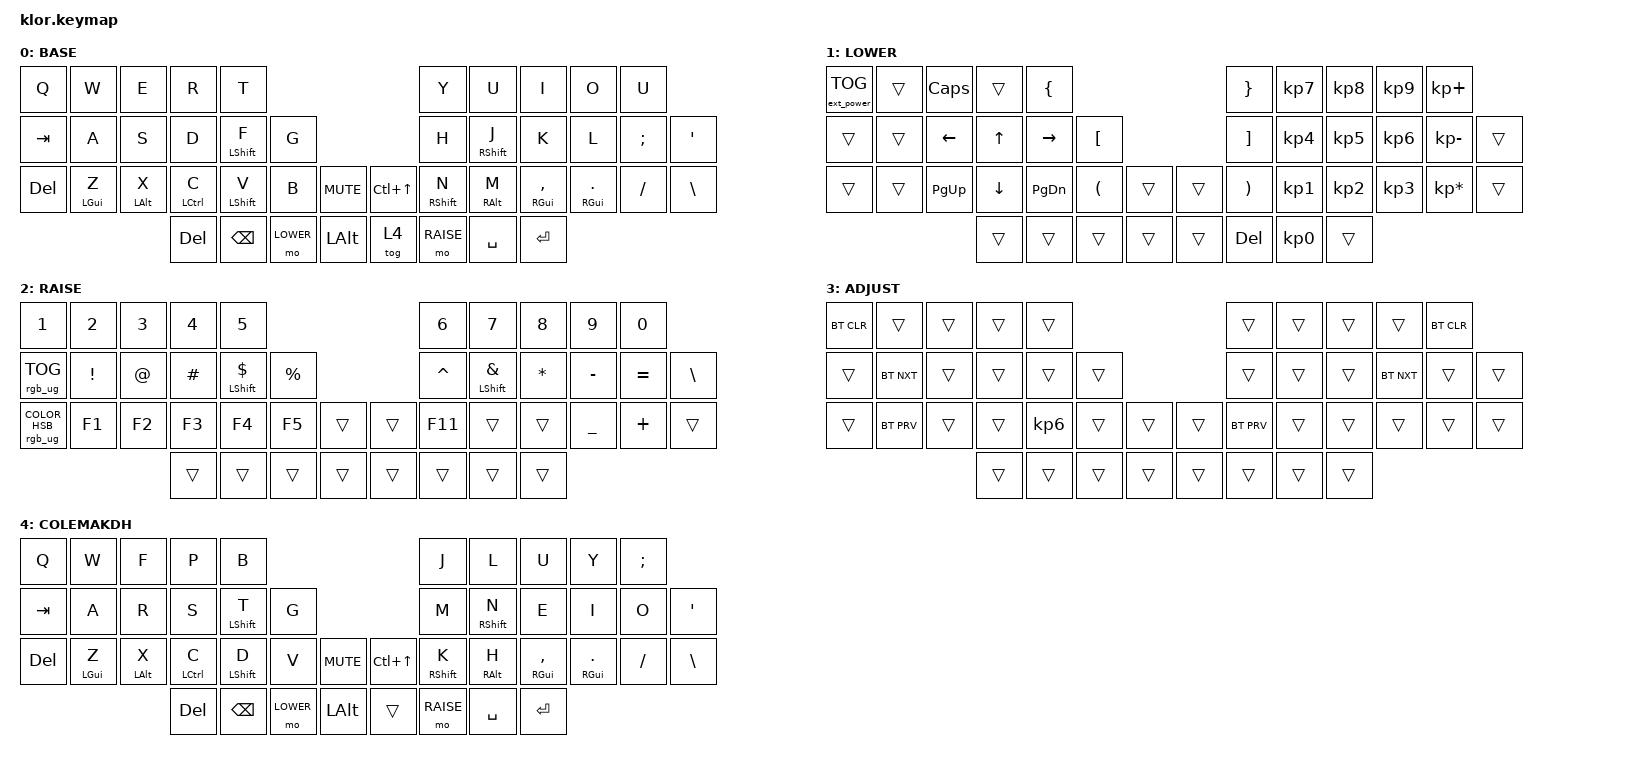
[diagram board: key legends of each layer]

//                               █         █    █            ▄▄▄▀▀▀▀▀▀▄▄▄        █▀▀▀▀▀▀▀▀▀▀█
//                               █        █     █          ▄▀            ▀▄      █          █
//                               █       █      █        ▄▀                ▀▄    █          █
//                               █      █       █        █                  █    █          █
//                               █     █        █       █                    █   █          █
//                               █    █         █       █                    █   █▄▄▄▄▄▄▄▄▄▄█
//                               █   █ █        █       █                    █   █      █
//                               █  █   █       █        █                  █    █       █
//                               █ █     █      █        ▀▄                ▄▀    █        █
//                               ██       █     █          ▀▄            ▄▀      █         █
//                               █         █    █▄▄▄▄▄▄▄▄    ▀▀▀▄▄▄▄▄▄▀▀▀        █          █
//
// ▄▄▄▄▄▄▄▄▄▄▄▄▄▄▄▄▄▄▄▄▄▄▄▄▄▄▄▄▄▄▄▄▄▄▄▄▄▄▄▄▄▄▄▄▄▄▄▄▄▄▄▄▄▄▄▄▄▄▄▄▄▄▄▄▄▄▄▄▄▄▄▄▄▄▄▄▄▄▄▄▄▄▄▄▄▄▄▄▄▄▄▄▄▄▄▄▄▄▄▄▄▄▄▄▄▄▄▄▄▄▄▄▄▄▄▄▄▄▄▄▄▄▄▄▄
       
#include <behaviors.dtsi>
#include <dt-bindings/zmk/keys.h>
#include <dt-bindings/zmk/backlight.h>
#include <dt-bindings/zmk/rgb.h>
#include <dt-bindings/zmk/bt.h>
#include <dt-bindings/zmk/outputs.h>
#include <dt-bindings/zmk/ext_power.h>


#define BASE   0
#define LOWER  1
#define RAISE  2
#define ADJUST 3
#define COLEMAKDH 4

/ {
    behaviors {
        hm: homerow_mods {
            compatible = "zmk,behavior-hold-tap";
            label = "HOMEROW_MODS";
            #binding-cells = <2>;
            tapping-term-ms = <150>;
            quick_tap_ms = <0>;
            flavor = "tap-preferred";
            bindings = <&kp>, <&kp>;
        };

&led_strip {
    chain-length = <21>;
};
        rgb_ug: rgb_ug {
            compatible = "zmk,behavior-rgb-underglow";
            label = "RGB_UG";
            #binding-cells = <2>;
        };

       bkl: bcklight {
            compatible = "zmk,behavior-backlight";
            label = "BCKLIGHT";
            #binding-cells = <2>;
       };
    };

    combos {
        compatible = "zmk,combos";
        combo_esc {
            timeout-ms = <50>;
            key-positions = <0 1>;
            bindings = <&kp ESC>;
        };
       left_bkt {
            bindings = <&kp LEFT_BRACKET>;
            key-positions = <1 2>;
            timeout-ms = <50>;
        };

        right_bkt {
            bindings = <&kp RIGHT_BRACKET>;
            key-positions = <2 3>;
            timeout-ms = <50>;
        };

        left_par {
            bindings = <&kp LEFT_PARENTHESIS>;
            key-positions = <12 13>;
            timeout-ms = <50>;
        };

        right_par {
            bindings = <&kp RIGHT_PARENTHESIS>;
            key-positions = <13 14>;
            timeout-ms = <50>;
        };

        left_brace {
            bindings = <&kp LEFT_BRACE>;
            key-positions = <25 26>;
            timeout-ms = <50>;
        };

        right_brace {
            bindings = <&kp RIGHT_BRACE>;
            key-positions = <26 27>;
            timeout-ms = <50>;
        };

        bac {
            bindings = <&kp BACKSLASH>;
            key-positions = <5 6>;
            timeout-ms = <50>;
        };

        pipe {
            bindings = <&kp PIPE>;
            key-positions = <3 4>;
            timeout-ms = <50>;
        };

        copy {
            bindings = <&kp LG(C)>;
            key-positions = <14 15>;
            timeout-ms = <50>;
        };

       paste {
            bindings = <&kp LG(V)>;
            key-positions = <16 17>;
            timeout-ms = <50>;
        };

        capslock {
            bindings = <&kp CAPS>;
            key-positions = <10 11>;
            timeout-ms = <50>;
        };

       studio {
            bindings = <&studio_unlock>;
            key-positions = <0 11>;
            timeout-ms = <50>;
        };
    };


        keymap {
                compatible = "zmk,keymap";
// ▄▄▄▄▄▄▄▄▄▄▄▄▄▄▄▄▄▄▄▄▄▄▄▄▄▄▄▄▄▄▄▄▄▄▄▄▄▄▄▄▄▄▄▄▄▄▄▄▄▄▄▄▄▄▄▄▄▄▄▄▄▄▄▄▄▄▄▄▄▄▄▄▄▄▄▄▄▄▄▄▄▄▄▄▄▄▄▄▄▄▄▄▄▄▄▄▄▄▄▄▄▄▄▄▄▄▄▄▄▄▄▄▄▄▄▄▄▄▄▄▄▄▄▄▄▄▄▄▄▄▄▄▄▄▄▄▄▄▄▄▄▄

                 base_layer {
// ┌───────────────────────────────────────────────────────────┐
label= "BASE"                                                ;
// └───────────────────────────────────────────────────────────┘
/*           ┌─────────┬─────────┬─────────┬─────────┬─────────┐                    ┌─────────┬─────────┬─────────┬─────────┬─────────┐
             │    Q    │    W    │    E    │    R    │    T    │                    │    Y    │    U    │    I    │    O    │    P    │   
   ┌─────────┼─────────┼─────────┼─────────┼─────────┼─────────┤                    ├─────────┼─────────┼─────────┼─────────┼─────────┼─────────┐
   │   TAB   │    A    │    S    │    D    │    F    │    G    │                    │    H    │    J    │    K    │    L    │    ;    │    "    │
   ├─────────┼─────────┼─────────┼─────────┼─────────┼─────────┤╭────────╮╭────────╮├─────────┼─────────┼─────────┼─────────┼─────────┼─────────┤
   │   DEL   │    Z    │    X    │    C    │    V    │    B    ││  MUTE  ││PLY/PSE ││    N    │    H    │    ,    │    .    │    /    │    \    │
   └─────────┴─────────┴─────────┼─────────┼─────────┼─────────┼╰────────╯╰────────╯┼─────────┼─────────┼─────────┼─────────┴─────────┴─────────┘
                                 │  DEL    │  BSPCE  │  LOWER  │   LOWER ││ TOG 4   │  SPACE  │  RAISE  │  ENTER  │  
                                 └─────────┴─────────┴─────────┴─────────┘└─────────┴─────────┴─────────┴─────────┘ */ 
 bindings = <
 //╷         ╷         ╷         ╷         ╷         ╷         ╷         ╷╷         ╷         ╷         ╷         ╷         ╷         ╷         ╷
              &kp Q     &kp W     &kp E     &kp R     &kp T                          &kp Y     &kp U     &kp I     &kp O     &kp U
    &kp TAB   &kp A     &kp S     &kp D   &hm LSHFT F &kp G                          &kp H   &hm RSHFT J &kp K     &kp L     &kp SEMI     &kp SQT
    &kp DEL   &hm LGUI Z     &hm LALT X     &hm LCTRL C     &hm LSHFT V     &kp B     &kp K_MUTE     &kp LC(UP)    &hm RSHFT N     &hm RALT M     &hm RGUI COMMA &hm RGUI DOT   &kp FSLH  &kp BSLH
                                  &kp DEL &kp BSPC &mo LOWER &kp LALT &tog 4 &mo RAISE &kp SPACE &kp RET     
                        >;
            sensor-bindings = <&inc_dec_kp C_VOL_UP C_VOL_DN &inc_dec_kp LC(LEFT) LC(RIGHT)>;
                };          

// ▄▄▄▄▄▄▄▄▄▄▄▄▄▄▄▄▄▄▄▄▄▄▄▄▄▄▄▄▄▄▄▄▄▄▄▄▄▄▄▄▄▄▄▄▄▄▄▄▄▄▄▄▄▄▄▄▄▄▄▄▄▄▄▄▄▄▄▄▄▄▄▄▄▄▄▄▄▄▄▄▄▄▄▄▄▄▄▄▄▄▄▄▄▄▄▄▄▄▄▄▄▄▄▄▄▄▄▄▄▄▄▄▄▄▄▄▄▄▄▄▄▄▄▄▄▄▄▄▄▄▄▄▄▄▄▄▄▄▄▄▄▄


                lower_layer {
// ┌───────────────────────────────────────────────────────────┐
label= "LOWER"                                                 ;
// └───────────────────────────────────────────────────────────┘
/*           ┌─────────┬─────────┬─────────┬─────────┬─────────┐                    ┌─────────┬─────────┬─────────┬─────────┬─────────┐
             │         │         │  CAPS   │         │    {    │                    │    }    │    7    │    8    │    9    │    +    │
   ┌─────────┼─────────┼─────────┼─────────┼─────────┼─────────┤                    ├─────────┼─────────┼─────────┼─────────┼─────────┼─────────┐
   │         │         │   LEFT  │    UP   │  RIGHT  │    [    │                    │    ]    │    4    │    5    │    6    │    -    │         │
   ├─────────┼─────────┼─────────┼─────────┼─────────┼─────────┤╭────────╮╭────────╮├─────────┼─────────┼─────────┼─────────┼─────────┼─────────┤
   │         │         │   P UP  │   DOWN  │ P DOWN  │    (    ││        ││        ││    )    │    1    │    2    │    3    │    *    │         │
   └─────────┴─────────┴─────────┼─────────┼─────────┼─────────┼╰────────╯╰────────╯┼─────────┼─────────┼─────────┼─────────┴─────────┴─────────┘
                                 │         │         │         │         ││         │         │    0    │         │  
                                 └─────────┴─────────┴─────────┴─────────┘└─────────┴─────────┴─────────┴─────────┘ */ 
 bindings = <
 //╷         ╷         ╷         ╷         ╷         ╷         ╷         ╷╷         ╷         ╷         ╷         ╷         ╷         ╷         ╷
    &ext_power EP_TOG   &trans    &kp CAPS    &trans    &kp LBRC                       &kp RBRC  &kp KP_N7 &kp KP_N8 &kp KP_N9 &kp KP_PLUS
    &trans    &trans    &kp LEFT  &kp UP  &kp RIGHT &kp LBKT                       &kp RBKT  &kp KP_N4 &kp KP_N5 &kp KP_N6 &kp KP_MINUS &trans
    &trans    &trans    &kp PG_UP &kp DOWN  &kp PG_DN &kp LPAR  &trans     &trans    &kp RPAR  &kp KP_N1 &kp KP_N2 &kp KP_N3 &kp KP_MULTIPLY &trans
                                  &trans    &trans    &trans    &trans     &trans    &kp DELETE &kp KP_N0 &trans  
                        >;
            sensor-bindings = <&inc_dec_kp C_VOL_UP C_VOL_DN &inc_dec_kp LC(LEFT) LC(RIGHT)>;
                };

// ▄▄▄▄▄▄▄▄▄▄▄▄▄▄▄▄▄▄▄▄▄▄▄▄▄▄▄▄▄▄▄▄▄▄▄▄▄▄▄▄▄▄▄▄▄▄▄▄▄▄▄▄▄▄▄▄▄▄▄▄▄▄▄▄▄▄▄▄▄▄▄▄▄▄▄▄▄▄▄▄▄▄▄▄▄▄▄▄▄▄▄▄▄▄▄▄▄▄▄▄▄▄▄▄▄▄▄▄▄▄▄▄▄▄▄▄▄▄▄▄▄▄▄▄▄


                raise_layer {
// ┌───────────────────────────────────────────────────────────┐
label= "RAISE"                                                 ;
// └───────────────────────────────────────────────────────────┘
/*           ┌─────────┬─────────┬─────────┬─────────┬─────────┐                    ┌─────────┬─────────┬─────────┬─────────┬─────────┐
             │         │         │         │         │         │                    │         │         │    Ü    │         │         │
   ┌─────────┼─────────┼─────────┼─────────┼─────────┼─────────┤                    ├─────────┼─────────┼─────────┼─────────┼─────────┼─────────┐
   │    Ä    │         │    ß    │         │         │         │                    │         │         │         │         │    Ö    │         │
   ├─────────┼─────────┼─────────┼─────────┼─────────┼─────────┤╭────────╮╭────────╮├─────────┼─────────┼─────────┼─────────┼─────────┼─────────┤
   │         │         │         │         │         │         ││        ││        ││         │         │         │         │         │         │
   └─────────┴─────────┴─────────┼─────────┼─────────┼─────────┼╰────────╯╰────────╯┼─────────┼─────────┼─────────┼─────────┴─────────┴─────────┘
                                 │ ADJUST  │         │         │         ││         │         │         │         │  
                                 └─────────┴─────────┴─────────┴─────────┘└─────────┴─────────┴─────────┴─────────┘ */ 
 bindings = <
 //╷         ╷       ╷       ╷       ╷       ╷              ╷         ╷╷         ╷         ╷                 ╷       ╷                ╷         ╷         ╷
              &kp N1  &kp N2  &kp N3  &kp N4  &kp N5                                &kp N6      &kp N7      &kp N8      &kp N9         &kp N0         
    &rgb_ug RGB_TOG &kp EXCL &kp AT  &kp HASH  &mt LSHFT DLLR  &kp PRCNT                 &kp CARET  &mt LSHFT AMPS     &kp ASTRK  &kp MINUS       &kp EQUAL    &kp BSLH  
    &rgb_ug RGB_COLOR_HSB(128,100,100)    &kp F1  &kp F2  &kp F3  &kp F4  &kp F5         &trans     &trans      &kp F11    &trans       &trans     &kp UNDER          &kp PLUS      &trans
                              &trans  &trans  &trans         &trans     &trans    &trans    &trans            &trans  
                        >;
            sensor-bindings = <&inc_dec_kp C_VOL_UP C_VOL_DN &inc_dec_kp LC(LEFT) LC(RIGHT)>;
                };

// ▄▄▄▄▄▄▄▄▄▄▄▄▄▄▄▄▄▄▄▄▄▄▄▄▄▄▄▄▄▄▄▄▄▄▄▄▄▄▄▄▄▄▄▄▄▄▄▄▄▄▄▄▄▄▄▄▄▄▄▄▄▄▄▄▄▄▄▄▄▄▄▄▄▄▄▄▄▄▄▄▄▄▄▄▄▄▄▄▄▄▄▄▄▄▄▄▄▄▄▄▄▄▄▄▄▄▄▄▄▄▄▄▄▄▄▄▄▄▄▄▄▄▄▄▄


                adjust_layer {
// ┌───────────────────────────────────────────────────────────┐
label= "ADJUST"                                                ;
// └───────────────────────────────────────────────────────────┘
/*           ┌─────────┬─────────┬─────────┬─────────┬─────────┐                    ┌─────────┬─────────┬─────────┬─────────┬─────────┐
             │         │         │         │         │         │                    │         │         │         │         │         │
   ┌─────────┼─────────┼─────────┼─────────┼─────────┼─────────┤                    ├─────────┼─────────┼─────────┼─────────┼─────────┼─────────┐
   │         │         │         │         │         │         │                    │         │         │         │         │         │         │
   ├─────────┼─────────┼─────────┼─────────┼─────────┼─────────┤╭────────╮╭────────╮├─────────┼─────────┼─────────┼─────────┼─────────┼─────────┤
   │         │         │         │         │         │         ││        ││        ││         │         │         │         │         │         │
   └─────────┴─────────┴─────────┼─────────┼─────────┼─────────┼╰────────╯╰────────╯┼─────────┼─────────┼─────────┼─────────┴─────────┴─────────┘
                                 │         │         │         │         ││         │         │         │         │  
                                 └─────────┴─────────┴─────────┴─────────┘└─────────┴─────────┴─────────┴─────────┘ */ 
 bindings = <
 //╷         ╷         ╷         ╷         ╷         ╷         ╷         ╷╷         ╷         ╷         ╷         ╷         ╷         ╷         ╷
             &bt BT_CLR &trans    &trans    &trans    &trans                         &trans    &trans    &trans    &trans    &bt BT_CLR   
    &trans   &bt BT_NXT &trans    &trans    &trans    &trans                         &trans    &trans    &trans    &bt BT_NXT &trans   &trans 
    &trans   &bt BT_PRV &trans    &trans    &kp KP_N6 &trans    &trans     &trans    &bt BT_PRV &trans   &trans    &trans    &trans    &trans    
                                  &trans    &trans    &trans    &trans     &trans    &trans    &trans    &trans    
                        >;
             sensor-bindings = <&inc_dec_kp C_VOL_UP C_VOL_DN &inc_dec_kp LC(LEFT) LC(RIGHT)>;
                };

// ▄▄▄▄▄▄▄▄▄▄▄▄▄▄▄▄▄▄▄▄▄▄▄▄▄▄▄▄▄▄▄▄▄▄▄▄▄▄▄▄▄▄▄▄▄▄▄▄▄▄▄▄▄▄▄▄▄▄▄▄▄▄▄▄▄▄▄▄▄▄▄▄▄▄▄▄▄▄▄▄▄▄▄▄▄▄▄▄▄▄▄▄▄▄▄▄▄▄▄▄▄▄▄▄▄▄▄▄▄▄▄▄▄▄▄▄▄▄▄▄▄▄▄▄▄


                colemakdh_layer {
// ┌───────────────────────────────────────────────────────────┐
label= "COLEMAKDH"                                               ;
// └───────────────────────────────────────────────────────────┘
/*           ┌─────────┬─────────┬─────────┬─────────┬─────────┐                    ┌─────────┬─────────┬─────────┬─────────┬─────────┐
             │    Q    │    W    │    F    │    P    │    B    │                    │    J    │    L    │    U    │    Y    │    ;    │   
   ┌─────────┼─────────┼─────────┼─────────┼─────────┼─────────┤                    ├─────────┼─────────┼─────────┼─────────┼─────────┼─────────┐
   │   TAB   │    A    │    R    │    S    │    T    │    G    │                    │    M    │    N    │    E    │    I    │    O    │    "    │
   ├─────────┼─────────┼─────────┼─────────┼─────────┼─────────┤╭────────╮╭────────╮├─────────┼─────────┼─────────┼─────────┼─────────┼─────────┤
   │   DEL   │    Z    │    X    │    C    │    D    │    V    ││  MUTE  ││PLY/PSE ││    K    │    H    │    ,    │    .    │    /    │    \    │
   └─────────┴─────────┴─────────┼─────────┼─────────┼─────────┼╰────────╯╰────────╯┼─────────┼─────────┼─────────┼─────────┴─────────┴─────────┘
                                 │  DEL    │  BSPCE  │  LOWER  │   LOWER ││ TOG 4   │  SPACE  │  RAISE  │  ENTER  │  
                                 └─────────┴─────────┴─────────┴─────────┘└─────────┴─────────┴─────────┴─────────┘ */ 
 bindings = <
 //╷         ╷         ╷         ╷         ╷         ╷         ╷         ╷╷         ╷         ╷         ╷         ╷         ╷         ╷         ╷
              &kp Q     &kp W     &kp F     &kp P     &kp B                          &kp J     &kp L     &kp U     &kp Y     &kp SEMI
    &kp TAB   &kp A          &kp R     &kp S   &hm LSHFT T &kp G                          &kp M   &hm RSHFT N &kp E     &kp I     &kp O     &kp SQT
    &kp DEL   &hm LGUI Z     &hm LALT X     &hm LCTRL C     &hm LSHFT D     &kp V     &kp K_MUTE     &kp LC(UP)    &hm RSHFT K     &hm RALT H     &hm RGUI COMMA &hm RGUI DOT   &kp FSLH  &kp BSLH
                                  &kp DEL &kp BSPC &mo LOWER &kp LALT   &trans  &mo RAISE &kp SPACE &kp RET    
                        >;
            sensor-bindings = <&inc_dec_kp C_VOL_UP C_VOL_DN &inc_dec_kp LC(LEFT) LC(RIGHT)>;
                };
        };
};
